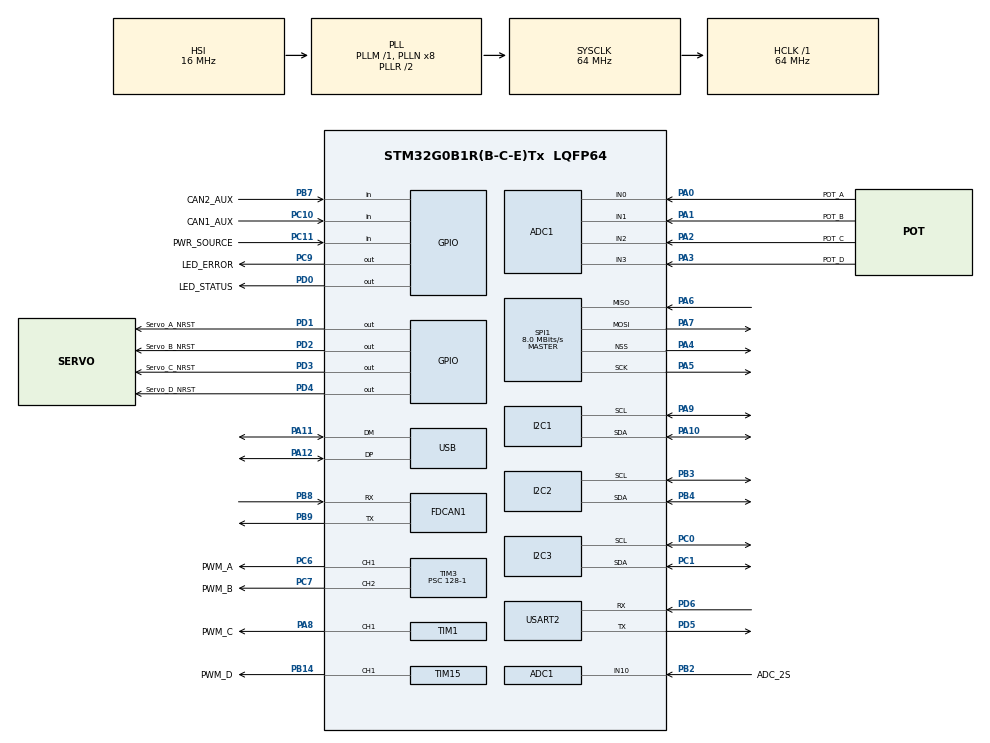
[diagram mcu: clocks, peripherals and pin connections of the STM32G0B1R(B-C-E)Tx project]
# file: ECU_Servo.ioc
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ADC1.ClockPrescaler=ADC_CLOCK_SYNC_PCLK_DIV4
ADC1.ContinuousConvMode=ENABLE
ADC1.DMAContinuousRequests=ENABLE
ADC1.EOCSelection=ADC_EOC_SEQ_CONV
ADC1.NbrOfConversion=1
ADC1.NbrOfConversionFlag=0
ADC1.OversamplingMode=ENABLE
ADC1.Ratio=ADC_OVERSAMPLING_RATIO_16
ADC1.RightBitShift=ADC_RIGHTBITSHIFT_4
ADC1.SamplingTimeCommon1=ADC_SAMPLETIME_160CYCLES_5
ADC1.SelectedChannel=ADC_CHANNEL_0|ADC_CHANNEL_1|ADC_CHANNEL_2|ADC_CHANNEL_3|ADC_CHANNEL_10
ADC1.Sequencer=NOT_FULLY_CONFIGURABLE
ADC1.TriggerFrequencyMode=ADC_TRIGGER_FREQ_HIGH
ADC1.master=1
Dma.ADC1.0.Direction=DMA_PERIPH_TO_MEMORY
Dma.ADC1.0.EventEnable=DISABLE
Dma.ADC1.0.Instance=DMA1_Channel1
Dma.ADC1.0.MemDataAlignment=DMA_MDATAALIGN_HALFWORD
Dma.ADC1.0.MemInc=DMA_MINC_ENABLE
Dma.ADC1.0.Mode=DMA_CIRCULAR
Dma.ADC1.0.PeriphDataAlignment=DMA_PDATAALIGN_HALFWORD
Dma.ADC1.0.PeriphInc=DMA_PINC_DISABLE
Dma.ADC1.0.Polarity=HAL_DMAMUX_REQ_GEN_RISING
Dma.ADC1.0.Priority=DMA_PRIORITY_LOW
Dma.ADC1.0.RequestNumber=1
Dma.ADC1.0.SignalID=NONE
Dma.ADC1.0.SyncEnable=DISABLE
Dma.ADC1.0.SyncPolarity=HAL_DMAMUX_SYNC_NO_EVENT
Dma.ADC1.0.SyncRequestNumber=1
Dma.ADC1.0.SyncSignalID=NONE
Dma.Request0=ADC1
FDCAN1.AutoRetransmission=ENABLE
FDCAN1.CalculateBaudRateNominal=500000
FDCAN1.CalculateTimeBitNominal=2000
FDCAN1.CalculateTimeQuantumNominal=31.25
FDCAN1.DataSyncJumpWidth=8
FDCAN1.DataTimeSeg1=23
FDCAN1.DataTimeSeg2=8
FDCAN1.FrameFormat=FDCAN_FRAME_FD_BRS
FDCAN1.Mode=FDCAN_MODE_NORMAL
FDCAN1.NominalPrescaler=2
FDCAN1.NominalSyncJumpWidth=16
FDCAN1.NominalTimeSeg1=47
FDCAN1.NominalTimeSeg2=16
FDCAN1.StdFiltersNbr=4
FDCAN1.TransmitPause=ENABLE
FDCAN1.TxFifoQueueMode=FDCAN_TX_QUEUE_OPERATION
I2C1.Timing=0x10B17DB5
I2C2.Timing=0x10B17DB5
I2C3.Timing=0x10B17DB5
Mcu.Family=STM32G0
Mcu.Name=STM32G0B1R(B-C-E)Tx
Mcu.Package=LQFP64
NVIC.ADC1_COMP_IRQn=true\:0\:0\:false\:false\:true\:true\:true\:true
NVIC.DMA1_Channel1_IRQn=true\:0\:0\:false\:false\:true\:false\:true\:true
NVIC.TIM14_IRQn=true\:0\:0\:false\:false\:true\:true\:true\:true
NVIC.TIM16_FDCAN_IT0_IRQn=true\:0\:0\:false\:false\:true\:true\:true\:true
NVIC.TIM17_FDCAN_IT1_IRQn=true\:0\:0\:false\:false\:true\:true\:true\:true
NVIC.USB_UCPD1_2_IRQn=true\:0\:0\:false\:false\:true\:true\:true\:true
PA0.GPIO_Label=POT_A
PA0.Mode=IN0
PA0.Signal=ADC1_IN0
PA1.GPIO_Label=POT_B
PA1.Mode=IN1
PA1.Signal=ADC1_IN1
PA10.Mode=I2C
PA10.Signal=I2C1_SDA
PA11\ [PA9].Mode=Device
PA11\ [PA9].Signal=USB_DM
PA12\ [PA10].Mode=Device
PA12\ [PA10].Signal=USB_DP
PA13.Mode=Serial_Wire
PA13.Signal=SYS_SWDIO
PA14-BOOT0.Mode=Serial_Wire
PA14-BOOT0.Signal=SYS_SWCLK
PA2.GPIO_Label=POT_C
PA2.Mode=IN2
PA2.Signal=ADC1_IN2
PA3.GPIO_Label=POT_D
PA3.Mode=IN3
PA3.Signal=ADC1_IN3
PA4.Mode=NSS_Signal_Hard_Output
PA4.Signal=SPI1_NSS
PA5.Mode=Full_Duplex_Master
PA5.Signal=SPI1_SCK
PA6.Mode=Full_Duplex_Master
PA6.Signal=SPI1_MISO
PA7.Mode=Full_Duplex_Master
PA7.Signal=SPI1_MOSI
PA8.GPIO_Label=PWM_C
PA8.Signal=S_TIM1_CH1
PA9.Mode=I2C
PA9.Signal=I2C1_SCL
PB14.GPIO_Label=PWM_D
PB14.Signal=S_TIM15_CH1
PB2.GPIO_Label=ADC_2S
PB2.Mode=IN10
PB2.Signal=ADC1_IN10
PB3.Mode=I2C
PB3.Signal=I2C2_SCL
PB4.Mode=I2C
PB4.Signal=I2C2_SDA
PB7.GPIO_Label=CAN2_AUX
PB7.Signal=GPIO_Input
PB8.Mode=FDCAN_Activate
PB8.Signal=FDCAN1_RX
PB9.Mode=FDCAN_Activate
PB9.Signal=FDCAN1_TX
PC0.Mode=I2C
PC0.Signal=I2C3_SCL
PC1.Mode=I2C
PC1.Signal=I2C3_SDA
PC10.GPIO_Label=CAN1_AUX
PC10.Signal=GPIO_Input
PC11.GPIO_Label=PWR_SOURCE
PC11.Signal=GPIO_Input
PC6.GPIO_Label=PWM_A
PC6.Signal=S_TIM3_CH1
PC7.GPIO_Label=PWM_B
PC7.Signal=S_TIM3_CH2
PC9.GPIO_Label=LED_ERROR
PC9.Signal=GPIO_Output
PD0.GPIO_Label=LED_STATUS
PD0.Signal=GPIO_Output
PD1.GPIO_Label=Servo_A_NRST
PD1.GPIO_ModeDefaultOutputPP=GPIO_MODE_OUTPUT_OD
PD1.GPIO_PuPd=GPIO_NOPULL
PD1.PinState=GPIO_PIN_SET
PD1.Signal=GPIO_Output
PD2.GPIO_Label=Servo_B_NRST
PD2.GPIO_ModeDefaultOutputPP=GPIO_MODE_OUTPUT_OD
PD2.GPIO_PuPd=GPIO_NOPULL
PD2.PinState=GPIO_PIN_SET
PD2.Signal=GPIO_Output
PD3.GPIO_Label=Servo_C_NRST
PD3.GPIO_ModeDefaultOutputPP=GPIO_MODE_OUTPUT_OD
PD3.GPIO_PuPd=GPIO_NOPULL
PD3.PinState=GPIO_PIN_SET
PD3.Signal=GPIO_Output
PD4.GPIO_Label=Servo_D_NRST
PD4.GPIO_ModeDefaultOutputPP=GPIO_MODE_OUTPUT_OD
PD4.GPIO_PuPd=GPIO_NOPULL
PD4.PinState=GPIO_PIN_SET
PD4.Signal=GPIO_Output
PD5.Mode=Asynchronous
PD5.Signal=USART2_TX
PD6.Mode=Asynchronous
PD6.Signal=USART2_RX
PF0-OSC_IN\ (PF0).Mode=HSE-External-Oscillator
PF0-OSC_IN\ (PF0).Signal=RCC_OSC_IN
PF1-OSC_OUT\ (PF1).Mode=HSE-External-Oscillator
PF1-OSC_OUT\ (PF1).Signal=RCC_OSC_OUT
ProjectManager.HeapSize=0x200
ProjectManager.StackSize=0x400
ProjectManager.TargetToolchain=CMake
RCC.ADCFreq_Value=64000000
RCC.AHBFreq_Value=64000000
RCC.CortexFreq_Value=64000000
RCC.EXTERNAL_CLOCK_VALUE=48000
RCC.HCLKFreq_Value=64000000
RCC.HSE_VALUE=12000000
RCC.HSI48_VALUE=48000000
RCC.HSI_VALUE=16000000
RCC.LSE_VALUE=32768
RCC.SYSCLKFreq_VALUE=64000000
RCC.SYSCLKSource=RCC_SYSCLKSOURCE_PLLCLK
RCC.USBFreq_Value=48000000
RCC.VCOOutputFreq_Value=128000000
SH.S_TIM15_CH1.0=TIM15_CH1,PWM Generation1 CH1
SH.S_TIM1_CH1.0=TIM1_CH1,PWM Generation1 CH1
SH.S_TIM3_CH1.0=TIM3_CH1,PWM Generation1 CH1
SH.S_TIM3_CH2.0=TIM3_CH2,PWM Generation2 CH2
SPI1.BaudRatePrescaler=SPI_BAUDRATEPRESCALER_8
SPI1.CalculateBaudRate=8.0 MBits/s
SPI1.Direction=SPI_DIRECTION_2LINES
SPI1.Mode=SPI_MODE_MASTER
SPI1.VirtualNSS=VM_NSSHARD
SPI1.VirtualType=VM_MASTER
TIM1.Channel-PWM\ Generation1\ CH1=TIM_CHANNEL_1
TIM1.OffStateIDLEMode=TIM_OSSI_DISABLE
TIM1.OffStateRunMode=TIM_OSSR_DISABLE
TIM1.Period=10000-1
TIM1.Prescaler=128-1
TIM14.Period=62500
TIM14.Prescaler=1024
TIM15.BreakPolarity=TIM_BREAKPOLARITY_LOW
TIM15.Channel-PWM\ Generation1\ CH1=TIM_CHANNEL_1
TIM15.OCPolarity_1=TIM_OCPOLARITY_HIGH
TIM15.OffStateIDLEMode=TIM_OSSI_DISABLE
TIM15.OffStateRunMode=TIM_OSSR_DISABLE
TIM15.Period=10000-1
TIM15.Prescaler=128-1
TIM2.Prescaler=63999
TIM3.Channel-PWM\ Generation1\ CH1=TIM_CHANNEL_1
TIM3.Channel-PWM\ Generation2\ CH2=TIM_CHANNEL_2
TIM3.OCPolarity_2=TIM_OCPOLARITY_HIGH
TIM3.Period=10000-1
TIM3.Prescaler=128-1
USART2.VirtualMode-Asynchronous=VM_ASYNC
USB_DEVICE.CLASS_NAME_FS=CDC
USB_DEVICE.VirtualMode=Cdc
USB_DEVICE.VirtualModeFS=Cdc_FS
VP_RTC_VS_RTC_Activate.Mode=RTC_Enabled
VP_SYS_VS_DBSignals.Mode=DisableDeadBatterySignals
VP_TIM14_VS_ClockSourceINT.Mode=Enable_Timer
VP_TIM1_VS_ClockSourceINT.Mode=Internal
VP_TIM2_VS_ClockSourceINT.Mode=Internal
VP_TIM3_VS_ClockSourceINT.Mode=Internal
VP_USB_DEVICE_VS_USB_DEVICE_CDC_FS.Mode=CDC_FS
board=custom

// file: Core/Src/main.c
/* USER CODE BEGIN Header */
/**
  ******************************************************************************
  * @file           : main.c
  * @brief          : Main program body
  ******************************************************************************
  * @attention
  *
  * Copyright (c) 2025 STMicroelectronics.
  * All rights reserved.
  *
  * This software is licensed under terms that can be found in the LICENSE file
  * in the root directory of this software component.
  * If no LICENSE file comes with this software, it is provided AS-IS.
  *
  ******************************************************************************
  */
/* USER CODE END Header */
#include "main.h"
#include "usb_device.h"

/* USER CODE BEGIN Includes */
#include "app.h"
/* USER CODE END Includes */

ADC_HandleTypeDef hadc1;
DMA_HandleTypeDef hdma_adc1;

FDCAN_HandleTypeDef hfdcan1;

I2C_HandleTypeDef hi2c1;
I2C_HandleTypeDef hi2c2;
I2C_HandleTypeDef hi2c3;

RTC_HandleTypeDef hrtc;

SPI_HandleTypeDef hspi1;

TIM_HandleTypeDef htim1;
TIM_HandleTypeDef htim2;
TIM_HandleTypeDef htim3;
TIM_HandleTypeDef htim14;
TIM_HandleTypeDef htim15;

UART_HandleTypeDef huart2;

void SystemClock_Config(void);
static void MX_GPIO_Init(void);
static void MX_DMA_Init(void);
static void MX_FDCAN1_Init(void);
static void MX_I2C1_Init(void);
static void MX_I2C2_Init(void);
static void MX_SPI1_Init(void);
static void MX_USART2_UART_Init(void);
static void MX_ADC1_Init(void);
static void MX_RTC_Init(void);
static void MX_TIM1_Init(void);
static void MX_TIM3_Init(void);
static void MX_TIM15_Init(void);
static void MX_I2C3_Init(void);
static void MX_TIM14_Init(void);
static void MX_TIM2_Init(void);

int main(void)
{

  /* MCU Configuration--------------------------------------------------------*/

  /* Reset of all peripherals, Initializes the Flash interface and the Systick. */
  HAL_Init();

  /* Configure the system clock */
  SystemClock_Config();

  /* USER CODE BEGIN SysInit */

  /*****************
   * Start TIM2 for timebase
   *****************/

  MX_TIM2_Init();

  // Set counter to zero
  __HAL_TIM_SET_COUNTER(&htim2, 0);

  // Start the timer
  if (HAL_TIM_Base_Start(&htim2) != HAL_OK) {
      Error_Handler();
  }

  /* USER CODE END SysInit */

  /* Initialize all configured peripherals */
  MX_GPIO_Init();
  MX_DMA_Init();
  MX_FDCAN1_Init();
  MX_I2C1_Init();
  MX_I2C2_Init();
  MX_SPI1_Init();
  MX_USART2_UART_Init();
  MX_ADC1_Init();
  MX_RTC_Init();
  MX_TIM1_Init();
  MX_TIM3_Init();
  MX_TIM15_Init();
  MX_I2C3_Init();
  //MX_USB_Device_Init();
  MX_TIM14_Init();
  MX_TIM2_Init();
  /* USER CODE BEGIN 2 */
  app_init(); // Initialize the application
  app_run(); // Run the application
  /* USER CODE END 2 */

  /* Infinite loop */
  while (1)
  {

  }
}

void SystemClock_Config(void)
{
  RCC_OscInitTypeDef RCC_OscInitStruct = {0};
  RCC_ClkInitTypeDef RCC_ClkInitStruct = {0};

  /** Configure the main internal regulator output voltage
  */
  HAL_PWREx_ControlVoltageScaling(PWR_REGULATOR_VOLTAGE_SCALE1);

  /** Initializes the RCC Oscillators according to the specified parameters
  * in the RCC_OscInitTypeDef structure.
  */
  RCC_OscInitStruct.OscillatorType = RCC_OSCILLATORTYPE_HSI|RCC_OSCILLATORTYPE_LSI
                              |RCC_OSCILLATORTYPE_HSI48;
  RCC_OscInitStruct.HSIState = RCC_HSI_ON;
  RCC_OscInitStruct.HSI48State = RCC_HSI48_ON;
  RCC_OscInitStruct.HSIDiv = RCC_HSI_DIV1;
  RCC_OscInitStruct.HSICalibrationValue = RCC_HSICALIBRATION_DEFAULT;
  RCC_OscInitStruct.LSIState = RCC_LSI_ON;
  RCC_OscInitStruct.PLL.PLLState = RCC_PLL_ON;
  RCC_OscInitStruct.PLL.PLLSource = RCC_PLLSOURCE_HSI;
  RCC_OscInitStruct.PLL.PLLM = RCC_PLLM_DIV1;
  RCC_OscInitStruct.PLL.PLLN = 8;
  RCC_OscInitStruct.PLL.PLLP = RCC_PLLP_DIV2;
  RCC_OscInitStruct.PLL.PLLQ = RCC_PLLQ_DIV2;
  RCC_OscInitStruct.PLL.PLLR = RCC_PLLR_DIV2;
  if (HAL_RCC_OscConfig(&RCC_OscInitStruct) != HAL_OK)
  {
    Error_Handler();
  }

  /** Initializes the CPU, AHB and APB buses clocks
  */
  RCC_ClkInitStruct.ClockType = RCC_CLOCKTYPE_HCLK|RCC_CLOCKTYPE_SYSCLK
                              |RCC_CLOCKTYPE_PCLK1;
  RCC_ClkInitStruct.SYSCLKSource = RCC_SYSCLKSOURCE_PLLCLK;
  RCC_ClkInitStruct.AHBCLKDivider = RCC_SYSCLK_DIV1;
  RCC_ClkInitStruct.APB1CLKDivider = RCC_HCLK_DIV1;

  if (HAL_RCC_ClockConfig(&RCC_ClkInitStruct, FLASH_LATENCY_2) != HAL_OK)
  {
    Error_Handler();
  }
}

static void MX_ADC1_Init(void)
{

  ADC_ChannelConfTypeDef sConfig = {0};

  /** Configure the global features of the ADC (Clock, Resolution, Data Alignment and number of conversion)
  */
  hadc1.Instance = ADC1;
  hadc1.Init.ClockPrescaler = ADC_CLOCK_SYNC_PCLK_DIV4;
  hadc1.Init.Resolution = ADC_RESOLUTION_12B;
  hadc1.Init.DataAlign = ADC_DATAALIGN_RIGHT;
  hadc1.Init.ScanConvMode = ADC_SCAN_SEQ_FIXED;
  hadc1.Init.EOCSelection = ADC_EOC_SEQ_CONV;
  hadc1.Init.LowPowerAutoWait = DISABLE;
  hadc1.Init.LowPowerAutoPowerOff = DISABLE;
  hadc1.Init.ContinuousConvMode = ENABLE;
  hadc1.Init.NbrOfConversion = 1;
  hadc1.Init.ExternalTrigConv = ADC_SOFTWARE_START;
  hadc1.Init.ExternalTrigConvEdge = ADC_EXTERNALTRIGCONVEDGE_NONE;
  hadc1.Init.DMAContinuousRequests = ENABLE;
  hadc1.Init.Overrun = ADC_OVR_DATA_PRESERVED;
  hadc1.Init.SamplingTimeCommon1 = ADC_SAMPLETIME_160CYCLES_5;
  hadc1.Init.OversamplingMode = ENABLE;
  hadc1.Init.Oversampling.Ratio = ADC_OVERSAMPLING_RATIO_16;
  hadc1.Init.Oversampling.RightBitShift = ADC_RIGHTBITSHIFT_4;
  hadc1.Init.Oversampling.TriggeredMode = ADC_TRIGGEREDMODE_SINGLE_TRIGGER;
  hadc1.Init.TriggerFrequencyMode = ADC_TRIGGER_FREQ_HIGH;
  if (HAL_ADC_Init(&hadc1) != HAL_OK)
  {
    Error_Handler();
  }

  /** Configure Regular Channel
  */
  sConfig.Channel = ADC_CHANNEL_0;
  sConfig.Rank = ADC_RANK_CHANNEL_NUMBER;
  if (HAL_ADC_ConfigChannel(&hadc1, &sConfig) != HAL_OK)
  {
    Error_Handler();
  }

  /** Configure Regular Channel
  */
  sConfig.Channel = ADC_CHANNEL_1;
  if (HAL_ADC_ConfigChannel(&hadc1, &sConfig) != HAL_OK)
  {
    Error_Handler();
  }

  /** Configure Regular Channel
  */
  sConfig.Channel = ADC_CHANNEL_2;
  if (HAL_ADC_ConfigChannel(&hadc1, &sConfig) != HAL_OK)
  {
    Error_Handler();
  }

  /** Configure Regular Channel
  */
  sConfig.Channel = ADC_CHANNEL_3;
  if (HAL_ADC_ConfigChannel(&hadc1, &sConfig) != HAL_OK)
  {
    Error_Handler();
  }

  /** Configure Regular Channel
  */
  sConfig.Channel = ADC_CHANNEL_10;
  if (HAL_ADC_ConfigChannel(&hadc1, &sConfig) != HAL_OK)
  {
    Error_Handler();
  }

}

static void MX_FDCAN1_Init(void)
{

  hfdcan1.Instance = FDCAN1;
  hfdcan1.Init.ClockDivider = FDCAN_CLOCK_DIV1;
  hfdcan1.Init.FrameFormat = FDCAN_FRAME_FD_BRS;
  hfdcan1.Init.Mode = FDCAN_MODE_NORMAL;
  hfdcan1.Init.AutoRetransmission = ENABLE;
  hfdcan1.Init.TransmitPause = ENABLE;
  hfdcan1.Init.ProtocolException = DISABLE;
  hfdcan1.Init.NominalPrescaler = 2;
  hfdcan1.Init.NominalSyncJumpWidth = 16;
  hfdcan1.Init.NominalTimeSeg1 = 47;
  hfdcan1.Init.NominalTimeSeg2 = 16;
  hfdcan1.Init.DataPrescaler = 1;
  hfdcan1.Init.DataSyncJumpWidth = 8;
  hfdcan1.Init.DataTimeSeg1 = 23;
  hfdcan1.Init.DataTimeSeg2 = 8;
  hfdcan1.Init.StdFiltersNbr = 4;
  hfdcan1.Init.ExtFiltersNbr = 0;
  hfdcan1.Init.TxFifoQueueMode = FDCAN_TX_QUEUE_OPERATION;
  if (HAL_FDCAN_Init(&hfdcan1) != HAL_OK)
  {
    Error_Handler();
  }

}

static void MX_I2C1_Init(void)
{

  hi2c1.Instance = I2C1;
  hi2c1.Init.Timing = 0x10B17DB5;
  hi2c1.Init.OwnAddress1 = 0;
  hi2c1.Init.AddressingMode = I2C_ADDRESSINGMODE_7BIT;
  hi2c1.Init.DualAddressMode = I2C_DUALADDRESS_DISABLE;
  hi2c1.Init.OwnAddress2 = 0;
  hi2c1.Init.OwnAddress2Masks = I2C_OA2_NOMASK;
  hi2c1.Init.GeneralCallMode = I2C_GENERALCALL_DISABLE;
  hi2c1.Init.NoStretchMode = I2C_NOSTRETCH_DISABLE;
  if (HAL_I2C_Init(&hi2c1) != HAL_OK)
  {
    Error_Handler();
  }

  /** Configure Analogue filter
  */
  if (HAL_I2CEx_ConfigAnalogFilter(&hi2c1, I2C_ANALOGFILTER_ENABLE) != HAL_OK)
  {
    Error_Handler();
  }

  /** Configure Digital filter
  */
  if (HAL_I2CEx_ConfigDigitalFilter(&hi2c1, 0) != HAL_OK)
  {
    Error_Handler();
  }

}

static void MX_I2C2_Init(void)
{

  hi2c2.Instance = I2C2;
  hi2c2.Init.Timing = 0x10B17DB5;
  hi2c2.Init.OwnAddress1 = 0;
  hi2c2.Init.AddressingMode = I2C_ADDRESSINGMODE_7BIT;
  hi2c2.Init.DualAddressMode = I2C_DUALADDRESS_DISABLE;
  hi2c2.Init.OwnAddress2 = 0;
  hi2c2.Init.OwnAddress2Masks = I2C_OA2_NOMASK;
  hi2c2.Init.GeneralCallMode = I2C_GENERALCALL_DISABLE;
  hi2c2.Init.NoStretchMode = I2C_NOSTRETCH_DISABLE;
  if (HAL_I2C_Init(&hi2c2) != HAL_OK)
  {
    Error_Handler();
  }

  /** Configure Analogue filter
  */
  if (HAL_I2CEx_ConfigAnalogFilter(&hi2c2, I2C_ANALOGFILTER_ENABLE) != HAL_OK)
  {
    Error_Handler();
  }

  /** Configure Digital filter
  */
  if (HAL_I2CEx_ConfigDigitalFilter(&hi2c2, 0) != HAL_OK)
  {
    Error_Handler();
  }

}

static void MX_I2C3_Init(void)
{

  hi2c3.Instance = I2C3;
  hi2c3.Init.Timing = 0x10B17DB5;
  hi2c3.Init.OwnAddress1 = 0;
  hi2c3.Init.AddressingMode = I2C_ADDRESSINGMODE_7BIT;
  hi2c3.Init.DualAddressMode = I2C_DUALADDRESS_DISABLE;
  hi2c3.Init.OwnAddress2 = 0;
  hi2c3.Init.OwnAddress2Masks = I2C_OA2_NOMASK;
  hi2c3.Init.GeneralCallMode = I2C_GENERALCALL_DISABLE;
  hi2c3.Init.NoStretchMode = I2C_NOSTRETCH_DISABLE;
  if (HAL_I2C_Init(&hi2c3) != HAL_OK)
  {
    Error_Handler();
  }

  /** Configure Analogue filter
  */
  if (HAL_I2CEx_ConfigAnalogFilter(&hi2c3, I2C_ANALOGFILTER_ENABLE) != HAL_OK)
  {
    Error_Handler();
  }

  /** Configure Digital filter
  */
  if (HAL_I2CEx_ConfigDigitalFilter(&hi2c3, 0) != HAL_OK)
  {
    Error_Handler();
  }

}

static void MX_RTC_Init(void)
{

  /** Initialize RTC Only
  */
  hrtc.Instance = RTC;
  hrtc.Init.HourFormat = RTC_HOURFORMAT_24;
  hrtc.Init.AsynchPrediv = 127;
  hrtc.Init.SynchPrediv = 255;
  hrtc.Init.OutPut = RTC_OUTPUT_DISABLE;
  hrtc.Init.OutPutRemap = RTC_OUTPUT_REMAP_NONE;
  hrtc.Init.OutPutPolarity = RTC_OUTPUT_POLARITY_HIGH;
  hrtc.Init.OutPutType = RTC_OUTPUT_TYPE_OPENDRAIN;
  hrtc.Init.OutPutPullUp = RTC_OUTPUT_PULLUP_NONE;
  if (HAL_RTC_Init(&hrtc) != HAL_OK)
  {
    Error_Handler();
  }

}

static void MX_SPI1_Init(void)
{

  /* SPI1 parameter configuration*/
  hspi1.Instance = SPI1;
  hspi1.Init.Mode = SPI_MODE_MASTER;
  hspi1.Init.Direction = SPI_DIRECTION_2LINES;
  hspi1.Init.DataSize = SPI_DATASIZE_4BIT;
  hspi1.Init.CLKPolarity = SPI_POLARITY_LOW;
  hspi1.Init.CLKPhase = SPI_PHASE_1EDGE;
  hspi1.Init.NSS = SPI_NSS_HARD_OUTPUT;
  hspi1.Init.BaudRatePrescaler = SPI_BAUDRATEPRESCALER_8;
  hspi1.Init.FirstBit = SPI_FIRSTBIT_MSB;
  hspi1.Init.TIMode = SPI_TIMODE_DISABLE;
  hspi1.Init.CRCCalculation = SPI_CRCCALCULATION_DISABLE;
  hspi1.Init.CRCPolynomial = 7;
  hspi1.Init.CRCLength = SPI_CRC_LENGTH_DATASIZE;
  hspi1.Init.NSSPMode = SPI_NSS_PULSE_ENABLE;
  if (HAL_SPI_Init(&hspi1) != HAL_OK)
  {
    Error_Handler();
  }

}

static void MX_TIM1_Init(void)
{

  TIM_ClockConfigTypeDef sClockSourceConfig = {0};
  TIM_MasterConfigTypeDef sMasterConfig = {0};
  TIM_OC_InitTypeDef sConfigOC = {0};
  TIM_BreakDeadTimeConfigTypeDef sBreakDeadTimeConfig = {0};

  htim1.Instance = TIM1;
  htim1.Init.Prescaler = 128-1;
  htim1.Init.CounterMode = TIM_COUNTERMODE_UP;
  htim1.Init.Period = 10000-1;
  htim1.Init.ClockDivision = TIM_CLOCKDIVISION_DIV1;
  htim1.Init.RepetitionCounter = 0;
  htim1.Init.AutoReloadPreload = TIM_AUTORELOAD_PRELOAD_DISABLE;
  if (HAL_TIM_Base_Init(&htim1) != HAL_OK)
  {
    Error_Handler();
  }
  sClockSourceConfig.ClockSource = TIM_CLOCKSOURCE_INTERNAL;
  if (HAL_TIM_ConfigClockSource(&htim1, &sClockSourceConfig) != HAL_OK)
  {
    Error_Handler();
  }
  if (HAL_TIM_PWM_Init(&htim1) != HAL_OK)
  {
    Error_Handler();
  }
  sMasterConfig.MasterOutputTrigger = TIM_TRGO_RESET;
  sMasterConfig.MasterOutputTrigger2 = TIM_TRGO2_RESET;
  sMasterConfig.MasterSlaveMode = TIM_MASTERSLAVEMODE_DISABLE;
  if (HAL_TIMEx_MasterConfigSynchronization(&htim1, &sMasterConfig) != HAL_OK)
  {
    Error_Handler();
  }
  sConfigOC.OCMode = TIM_OCMODE_PWM1;
  sConfigOC.Pulse = 0;
  sConfigOC.OCPolarity = TIM_OCPOLARITY_HIGH;
  sConfigOC.OCNPolarity = TIM_OCNPOLARITY_HIGH;
  sConfigOC.OCFastMode = TIM_OCFAST_DISABLE;
  sConfigOC.OCIdleState = TIM_OCIDLESTATE_RESET;
  sConfigOC.OCNIdleState = TIM_OCNIDLESTATE_RESET;
  if (HAL_TIM_PWM_ConfigChannel(&htim1, &sConfigOC, TIM_CHANNEL_1) != HAL_OK)
  {
    Error_Handler();
  }
  sBreakDeadTimeConfig.OffStateRunMode = TIM_OSSR_DISABLE;
  sBreakDeadTimeConfig.OffStateIDLEMode = TIM_OSSI_DISABLE;
  sBreakDeadTimeConfig.LockLevel = TIM_LOCKLEVEL_OFF;
  sBreakDeadTimeConfig.DeadTime = 0;
  sBreakDeadTimeConfig.BreakState = TIM_BREAK_DISABLE;
  sBreakDeadTimeConfig.BreakPolarity = TIM_BREAKPOLARITY_HIGH;
  sBreakDeadTimeConfig.BreakFilter = 0;
  sBreakDeadTimeConfig.BreakAFMode = TIM_BREAK_AFMODE_INPUT;
  sBreakDeadTimeConfig.Break2State = TIM_BREAK2_DISABLE;
  sBreakDeadTimeConfig.Break2Polarity = TIM_BREAK2POLARITY_HIGH;
  sBreakDeadTimeConfig.Break2Filter = 0;
  sBreakDeadTimeConfig.Break2AFMode = TIM_BREAK_AFMODE_INPUT;
  sBreakDeadTimeConfig.AutomaticOutput = TIM_AUTOMATICOUTPUT_DISABLE;
  if (HAL_TIMEx_ConfigBreakDeadTime(&htim1, &sBreakDeadTimeConfig) != HAL_OK)
  {
    Error_Handler();
  }
  HAL_TIM_MspPostInit(&htim1);

}

static void MX_TIM2_Init(void)
{

  TIM_ClockConfigTypeDef sClockSourceConfig = {0};
  TIM_MasterConfigTypeDef sMasterConfig = {0};

  htim2.Instance = TIM2;
  htim2.Init.Prescaler = 63999;
  htim2.Init.CounterMode = TIM_COUNTERMODE_UP;
  htim2.Init.Period = 4294967295;
  htim2.Init.ClockDivision = TIM_CLOCKDIVISION_DIV1;
  htim2.Init.AutoReloadPreload = TIM_AUTORELOAD_PRELOAD_DISABLE;
  if (HAL_TIM_Base_Init(&htim2) != HAL_OK)
  {
    Error_Handler();
  }
  sClockSourceConfig.ClockSource = TIM_CLOCKSOURCE_INTERNAL;
  if (HAL_TIM_ConfigClockSource(&htim2, &sClockSourceConfig) != HAL_OK)
  {
    Error_Handler();
  }
  sMasterConfig.MasterOutputTrigger = TIM_TRGO_RESET;
  sMasterConfig.MasterSlaveMode = TIM_MASTERSLAVEMODE_DISABLE;
  if (HAL_TIMEx_MasterConfigSynchronization(&htim2, &sMasterConfig) != HAL_OK)
  {
    Error_Handler();
  }

}

static void MX_TIM3_Init(void)
{

  TIM_ClockConfigTypeDef sClockSourceConfig = {0};
  TIM_MasterConfigTypeDef sMasterConfig = {0};
  TIM_OC_InitTypeDef sConfigOC = {0};

  htim3.Instance = TIM3;
  htim3.Init.Prescaler = 128-1;
  htim3.Init.CounterMode = TIM_COUNTERMODE_UP;
  htim3.Init.Period = 10000-1;
  htim3.Init.ClockDivision = TIM_CLOCKDIVISION_DIV1;
  htim3.Init.AutoReloadPreload = TIM_AUTORELOAD_PRELOAD_DISABLE;
  if (HAL_TIM_Base_Init(&htim3) != HAL_OK)
  {
    Error_Handler();
  }
  sClockSourceConfig.ClockSource = TIM_CLOCKSOURCE_INTERNAL;
  if (HAL_TIM_ConfigClockSource(&htim3, &sClockSourceConfig) != HAL_OK)
  {
    Error_Handler();
  }
  if (HAL_TIM_PWM_Init(&htim3) != HAL_OK)
  {
    Error_Handler();
  }
  sMasterConfig.MasterOutputTrigger = TIM_TRGO_RESET;
  sMasterConfig.MasterSlaveMode = TIM_MASTERSLAVEMODE_DISABLE;
  if (HAL_TIMEx_MasterConfigSynchronization(&htim3, &sMasterConfig) != HAL_OK)
  {
    Error_Handler();
  }
  sConfigOC.OCMode = TIM_OCMODE_PWM1;
  sConfigOC.Pulse = 0;
  sConfigOC.OCPolarity = TIM_OCPOLARITY_HIGH;
  sConfigOC.OCFastMode = TIM_OCFAST_DISABLE;
  if (HAL_TIM_PWM_ConfigChannel(&htim3, &sConfigOC, TIM_CHANNEL_1) != HAL_OK)
  {
    Error_Handler();
  }
  if (HAL_TIM_PWM_ConfigChannel(&htim3, &sConfigOC, TIM_CHANNEL_2) != HAL_OK)
  {
    Error_Handler();
  }
  HAL_TIM_MspPostInit(&htim3);

}

static void MX_TIM14_Init(void)
{

  htim14.Instance = TIM14;
  htim14.Init.Prescaler = 1024;
  htim14.Init.CounterMode = TIM_COUNTERMODE_UP;
  htim14.Init.Period = 62500;
  htim14.Init.ClockDivision = TIM_CLOCKDIVISION_DIV1;
  htim14.Init.AutoReloadPreload = TIM_AUTORELOAD_PRELOAD_DISABLE;
  if (HAL_TIM_Base_Init(&htim14) != HAL_OK)
  {
    Error_Handler();
  }

}

static void MX_TIM15_Init(void)
{

  TIM_MasterConfigTypeDef sMasterConfig = {0};
  TIM_OC_InitTypeDef sConfigOC = {0};
  TIM_BreakDeadTimeConfigTypeDef sBreakDeadTimeConfig = {0};

  htim15.Instance = TIM15;
  htim15.Init.Prescaler = 128-1;
  htim15.Init.CounterMode = TIM_COUNTERMODE_UP;
  htim15.Init.Period = 10000-1;
  htim15.Init.ClockDivision = TIM_CLOCKDIVISION_DIV1;
  htim15.Init.RepetitionCounter = 0;
  htim15.Init.AutoReloadPreload = TIM_AUTORELOAD_PRELOAD_DISABLE;
  if (HAL_TIM_PWM_Init(&htim15) != HAL_OK)
  {
    Error_Handler();
  }
  sMasterConfig.MasterOutputTrigger = TIM_TRGO_RESET;
  sMasterConfig.MasterSlaveMode = TIM_MASTERSLAVEMODE_DISABLE;
  if (HAL_TIMEx_MasterConfigSynchronization(&htim15, &sMasterConfig) != HAL_OK)
  {
    Error_Handler();
  }
  sConfigOC.OCMode = TIM_OCMODE_PWM1;
  sConfigOC.Pulse = 0;
  sConfigOC.OCPolarity = TIM_OCPOLARITY_HIGH;
  sConfigOC.OCNPolarity = TIM_OCNPOLARITY_HIGH;
  sConfigOC.OCFastMode = TIM_OCFAST_DISABLE;
  sConfigOC.OCIdleState = TIM_OCIDLESTATE_RESET;
  sConfigOC.OCNIdleState = TIM_OCNIDLESTATE_RESET;
  if (HAL_TIM_PWM_ConfigChannel(&htim15, &sConfigOC, TIM_CHANNEL_1) != HAL_OK)
  {
    Error_Handler();
  }
  sBreakDeadTimeConfig.OffStateRunMode = TIM_OSSR_DISABLE;
  sBreakDeadTimeConfig.OffStateIDLEMode = TIM_OSSI_DISABLE;
  sBreakDeadTimeConfig.LockLevel = TIM_LOCKLEVEL_OFF;
  sBreakDeadTimeConfig.DeadTime = 0;
  sBreakDeadTimeConfig.BreakState = TIM_BREAK_DISABLE;
  sBreakDeadTimeConfig.BreakPolarity = TIM_BREAKPOLARITY_LOW;
  sBreakDeadTimeConfig.BreakFilter = 0;
  sBreakDeadTimeConfig.AutomaticOutput = TIM_AUTOMATICOUTPUT_DISABLE;
  if (HAL_TIMEx_ConfigBreakDeadTime(&htim15, &sBreakDeadTimeConfig) != HAL_OK)
  {
    Error_Handler();
  }
  HAL_TIM_MspPostInit(&htim15);

}

static void MX_USART2_UART_Init(void)
{

  huart2.Instance = USART2;
  huart2.Init.BaudRate = 115200;
  huart2.Init.WordLength = UART_WORDLENGTH_8B;
  huart2.Init.StopBits = UART_STOPBITS_1;
  huart2.Init.Parity = UART_PARITY_NONE;
  huart2.Init.Mode = UART_MODE_TX_RX;
  huart2.Init.HwFlowCtl = UART_HWCONTROL_NONE;
  huart2.Init.OverSampling = UART_OVERSAMPLING_16;
  huart2.Init.OneBitSampling = UART_ONE_BIT_SAMPLE_DISABLE;
  huart2.Init.ClockPrescaler = UART_PRESCALER_DIV1;
  huart2.AdvancedInit.AdvFeatureInit = UART_ADVFEATURE_NO_INIT;
  if (HAL_UART_Init(&huart2) != HAL_OK)
  {
    Error_Handler();
  }
  if (HAL_UARTEx_SetTxFifoThreshold(&huart2, UART_TXFIFO_THRESHOLD_1_8) != HAL_OK)
  {
    Error_Handler();
  }
  if (HAL_UARTEx_SetRxFifoThreshold(&huart2, UART_RXFIFO_THRESHOLD_1_8) != HAL_OK)
  {
    Error_Handler();
  }
  if (HAL_UARTEx_DisableFifoMode(&huart2) != HAL_OK)
  {
    Error_Handler();
  }

}

static void MX_DMA_Init(void)
{

  /* DMA controller clock enable */
  __HAL_RCC_DMA1_CLK_ENABLE();

  /* DMA interrupt init */
  /* DMA1_Channel1_IRQn interrupt configuration */
  HAL_NVIC_SetPriority(DMA1_Channel1_IRQn, 0, 0);
  HAL_NVIC_EnableIRQ(DMA1_Channel1_IRQn);

}

static void MX_GPIO_Init(void)
{
  GPIO_InitTypeDef GPIO_InitStruct = {0};

  /* GPIO Ports Clock Enable */
  __HAL_RCC_GPIOC_CLK_ENABLE();
  __HAL_RCC_GPIOF_CLK_ENABLE();
  __HAL_RCC_GPIOA_CLK_ENABLE();
  __HAL_RCC_GPIOB_CLK_ENABLE();
  __HAL_RCC_GPIOD_CLK_ENABLE();

  /*Configure GPIO pin Output Level */
  HAL_GPIO_WritePin(LED_ERROR_GPIO_Port, LED_ERROR_Pin, GPIO_PIN_RESET);

  /*Configure GPIO pin Output Level */
  HAL_GPIO_WritePin(LED_STATUS_GPIO_Port, LED_STATUS_Pin, GPIO_PIN_RESET);

  /*Configure GPIO pin Output Level */
  HAL_GPIO_WritePin(GPIOD, Servo_A_NRST_Pin|Servo_B_NRST_Pin|Servo_C_NRST_Pin|Servo_D_NRST_Pin, GPIO_PIN_SET);

  /*Configure GPIO pins : PWR_SOURCE_Pin CAN1_AUX_Pin */
  GPIO_InitStruct.Pin = PWR_SOURCE_Pin|CAN1_AUX_Pin;
  GPIO_InitStruct.Mode = GPIO_MODE_INPUT;
  GPIO_InitStruct.Pull = GPIO_NOPULL;
  HAL_GPIO_Init(GPIOC, &GPIO_InitStruct);

  /*Configure GPIO pin : LED_ERROR_Pin */
  GPIO_InitStruct.Pin = LED_ERROR_Pin;
  GPIO_InitStruct.Mode = GPIO_MODE_OUTPUT_PP;
  GPIO_InitStruct.Pull = GPIO_NOPULL;
  GPIO_InitStruct.Speed = GPIO_SPEED_FREQ_LOW;
  HAL_GPIO_Init(LED_ERROR_GPIO_Port, &GPIO_InitStruct);

  /*Configure GPIO pin : LED_STATUS_Pin */
  GPIO_InitStruct.Pin = LED_STATUS_Pin;
  GPIO_InitStruct.Mode = GPIO_MODE_OUTPUT_PP;
  GPIO_InitStruct.Pull = GPIO_NOPULL;
  GPIO_InitStruct.Speed = GPIO_SPEED_FREQ_LOW;
  HAL_GPIO_Init(LED_STATUS_GPIO_Port, &GPIO_InitStruct);

  /*Configure GPIO pins : Servo_A_NRST_Pin Servo_B_NRST_Pin Servo_C_NRST_Pin Servo_D_NRST_Pin */
  GPIO_InitStruct.Pin = Servo_A_NRST_Pin|Servo_B_NRST_Pin|Servo_C_NRST_Pin|Servo_D_NRST_Pin;
  GPIO_InitStruct.Mode = GPIO_MODE_OUTPUT_OD;
  GPIO_InitStruct.Pull = GPIO_NOPULL;
  GPIO_InitStruct.Speed = GPIO_SPEED_FREQ_LOW;
  HAL_GPIO_Init(GPIOD, &GPIO_InitStruct);

  /*Configure GPIO pin : CAN2_AUX_Pin */
  GPIO_InitStruct.Pin = CAN2_AUX_Pin;
  GPIO_InitStruct.Mode = GPIO_MODE_INPUT;
  GPIO_InitStruct.Pull = GPIO_NOPULL;
  HAL_GPIO_Init(CAN2_AUX_GPIO_Port, &GPIO_InitStruct);

}

void Error_Handler(void)
{
  __disable_irq();
  while (1)
  {
  }
}
